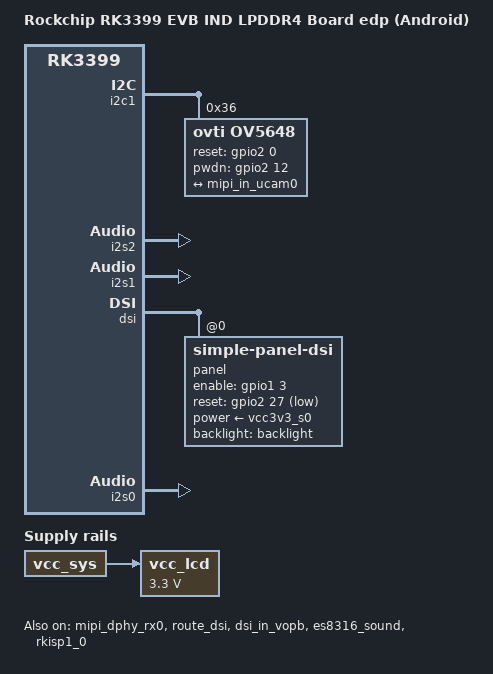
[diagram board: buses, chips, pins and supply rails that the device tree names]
// SPDX-License-Identifier: (GPL-2.0+ OR MIT)
/*
 * Copyright (c) 2019 Fuzhou Rockchip Electronics Co., Ltd
 */

/dts-v1/;

#include "rk3399-evb-ind-r70.dtsi"
#include "rk3399-android.dtsi"

/ {
	model = "Rockchip RK3399 EVB IND LPDDR4 Board edp (Android)";
	compatible = "rockchip,android", "rockchip,rk3399-evb-ind-lpddr4-android-r70", "rockchip,rk3399";
	chosen: chosen {
		bootargs = "earlycon=uart8250,mmio32,0xff1a0000 console=ttyFIQ0 androidboot.baseband=N/A androidboot.veritymode=enforcing androidboot.hardware=rk30board androidboot.console=ttyFIQ0 init=/init initrd=0x62000001,0x00800000 coherent_pool=1m";
	};

	iram: sram@ff8d0000 {
		compatible = "mmio-sram";
		reg = <0x0 0xff8d0000 0x0 0x20000>;
	};

	vcc_lcd: vcc-lcd {
		compatible = "regulator-fixed";
		regulator-name = "vcc_lcd";
		startup-delay-us = <20000>;
		enable-active-high;
		regulator-min-microvolt = <3300000>;
		regulator-max-microvolt = <3300000>;
		regulator-boot-on;
		vin-supply = <&vcc_sys>;
	};


	test-power {
		status = "okay";
	};
};

&backlight {
	enable-gpios = <&gpio1 2 GPIO_ACTIVE_HIGH>;
};

&dmac_bus {
	iram = <&iram>;
	rockchip,force-iram;
};

&dp_sound {
	status = "disabled";
};
/*
&edp {
	status = "disabled";
	force-hpd;

	ports {
		port@1 {
			reg = <1>;

			edp_out: endpoint {
				remote-endpoint = <&panel_in>;
			};
		};
	};
};

&edp_in_vopl {
	status = "disabled";
};
*/
&i2c1 {
	status = "okay";
	ov5648: ov5648@36 {
		compatible = "ovti,ov5648";
		status = "okay";
		reg = <0x36>;
		clocks = <&cru SCLK_CIF_OUT>;
		clock-names = "xvclk";
		/* avdd-supply = <>; */
		/* dvdd-supply = <>; */
		/* dovdd-supply = <>; */
		/* reset-gpios = <>; */
		//dovdd-supply = <&vcc1v8_dvp>;          
		reset-gpios = <&gpio2 0 GPIO_ACTIVE_HIGH>; 
		pwdn-gpios = <&gpio2 12 GPIO_ACTIVE_HIGH>;
		pinctrl-names = "rockchip,camera_default";
		pinctrl-0 = <&cif_clkout>;
		rockchip,camera-module-index = <0>;
		rockchip,camera-module-facing = "front";
		rockchip,camera-module-name = "default";
		rockchip,camera-module-lens-name = "default";                

		port {
			ucam_out0: endpoint {
				remote-endpoint = <&mipi_in_ucam0>;
				//remote-endpoint = <&mipi_in_ucam1>;
				data-lanes = <1 2>;
			};
		};
	};

};

&i2s2 {
	#sound-dai-cells = <0>;
	status = "okay";
};

&isp0_mmu {
	status = "okay";
};

&isp1_mmu {
	status = "okay";
};

&mipi_dphy_rx0 {
	status = "okay";

	ports {
		#address-cells = <1>;
		#size-cells = <0>;

		port@0 {
			reg = <0>;
			#address-cells = <1>;
			#size-cells = <0>;

			mipi_in_ucam0: endpoint@1 {
				reg = <1>;
				remote-endpoint = <&ucam_out0>;
				data-lanes = <1 2>;
			};
		};

		port@1 {
			reg = <1>;
			#address-cells = <1>;
			#size-cells = <0>;

			dphy_rx0_out: endpoint@0 {
				reg = <0>;
				remote-endpoint = <&isp0_mipi_in>;
			};
		};
	};
};
/*
&mipi_dphy_tx1rx1 {
	status = "okay";

	ports {
		#address-cells = <1>;
		#size-cells = <0>;

		port@0 {
			reg = <0>;
			#address-cells = <1>;
			#size-cells = <0>;

			mipi_in_ucam1: endpoint@1 {
				reg = <1>;
				remote-endpoint = <&ucam_out1>;
				data-lanes = <1 2>;
			};
		};

		port@1 {
			reg = <1>;
			#address-cells = <1>;
			#size-cells = <0>;

			dphy_tx1rx1_out: endpoint@0 {
				reg = <0>;
				remote-endpoint = <&isp1_mipi_in>;
			};
		};
	};
};
*/
&hdmi_sound {
	status = "disabled";
};

&route_dsi {
	status = "okay";
};

&dsi_in_vopl {
	status = "disabled";
};

&dsi_in_vopb {
	status = "okay";
};

&route_hdmi {
	status = "disabled";
	connect = <&vopl_out_hdmi>;
};

&i2s1 {
	#sound-dai-cells = <0>;
	status = "okay";
};

&es8316_sound {
	status = "okay";
};

&hdmi_in_vopb {
	status = "disabled";
};

&rkisp1_0 {
	status = "okay";

	port {
		#address-cells = <1>;
		#size-cells = <0>;

		isp0_mipi_in: endpoint@0 {
			reg = <0>;
			remote-endpoint = <&dphy_rx0_out>;
		};
	};
};

//JL101-CC1001-27F
&dsi {
	status = "okay";
	rockchip,lane-rate = <480>;
	panel@0 {
		compatible ="simple-panel-dsi";
		reg = <0>;
		backlight = <&backlight>;
		power-supply = <&vcc3v3_s0>;
		enable-gpios = <&gpio1 3 GPIO_ACTIVE_HIGH>;
		reset-gpios = <&gpio2 27 GPIO_ACTIVE_LOW>;
		
		dsi,flags = <(MIPI_DSI_MODE_VIDEO | MIPI_DSI_MODE_VIDEO_BURST)>;
		dsi,format = <MIPI_DSI_FMT_RGB888>;
		dsi,lanes = <4>;
		reset-delay-ms = <20>;
		init-delay-ms = <20>;
		enable-delay-ms = <120>;
		prepare-delay-ms = <120>;

		panel-init-sequence = [
        15 00 02 E0 00
		15 00 02 E1 93
		15 00 02 E2 65
		15 00 02 E3 F8
		15 00 02 80 03
		15 00 02 E0 01
		15 00 02 00 00
		15 00 02 01 5C
		15 00 02 17 00
		15 00 02 18 D7
		15 00 02 19 01
		15 00 02 1A 00
		15 00 02 1B D7		
		15 00 02 1C 01
		15 00 02 1F 70
		15 00 02 20 2D
		15 00 02 21 2D
		15 00 02 22 7E		
		15 00 02 24 FD
		15 00 02 37 19
		15 00 02 35 28
		15 00 02 38 05
		15 00 02 39 08
		15 00 02 3A 12
		15 00 02 3C 7E
		15 00 02 3D FF
		15 00 02 3E FF
		15 00 02 3F 7F
		15 00 02 0C 74
		15 00 02 40 06
		15 00 02 41 A0
		15 00 02 43 1E
		15 00 02 44 0B	
		15 00 02 55 01
		15 00 02 56 01
		15 00 02 57 6A
		15 00 02 58 09
		15 00 02 59 0A
		15 00 02 5A 2E
		15 00 02 5B 1A
		15 00 02 5C 15
		15 00 02 5D 7F		
		15 00 02 5E 5D
		15 00 02 5F 4B
		15 00 02 60 3E
		15 00 02 61 3A
		15 00 02 62 2B
		15 00 02 63 2F		
		15 00 02 64 19
		15 00 02 65 32
		15 00 02 66 31
		15 00 02 67 31
		15 00 02 68 4F
		15 00 02 69 3E
		15 00 02 6A 47
		15 00 02 6B 36
		15 00 02 6C 31
		15 00 02 6D 24
		15 00 02 6E 12
		15 00 02 6F 02
		15 00 02 70 7F		
		15 00 02 71 5D
		15 00 02 72 4B
		15 00 02 73 3E
		15 00 02 74 3A		
		15 00 02 75 2B
		15 00 02 76 2F
		15 00 02 77 19
		15 00 02 78 32
		15 00 02 79 31		
		15 00 02 7A 31
		15 00 02 7B 4F
		15 00 02 7C 3E
		15 00 02 7D 47
		15 00 02 7E 36		
		15 00 02 7F 31
		15 00 02 80 24
		15 00 02 81 12
		15 00 02 82 02
		15 00 02 E0 02
		15 00 02 00 52
		15 00 02 01 55
		15 00 02 02 55		
		15 00 02 03 50
		15 00 02 04 77
		15 00 02 05 57
		15 00 02 06 55
		15 00 02 07 4E
		15 00 02 08 4C
		15 00 02 09 5F		
		15 00 02 0A 4A
		15 00 02 0B 48
		15 00 02 0C 55
		15 00 02 0D 46
		15 00 02 0E 44
		15 00 02 0F 40		
		15 00 02 10 55
		15 00 02 11 55
		15 00 02 12 55
		15 00 02 13 55
		15 00 02 14 55
		15 00 02 15 55
		15 00 02 16 53		
		15 00 02 17 55
		15 00 02 18 55
		15 00 02 19 51
		15 00 02 1A 77
		15 00 02 1B 57
		15 00 02 1C 55
		15 00 02 1D 4F		
		15 00 02 1E 4D
		15 00 02 1F 5F
		15 00 02 20 4B
		15 00 02 21 49
		15 00 02 22 55
		15 00 02 23 47		
		15 00 02 24 45
		15 00 02 25 41
		15 00 02 26 55
		15 00 02 27 55		
		15 00 02 28 55
		15 00 02 29 55
		15 00 02 2A 55
		15 00 02 2B 55
		15 00 02 2C 13
		15 00 02 2D 15				
		15 00 02 2E 15
		15 00 02 2F 01
		15 00 02 30 37
		15 00 02 31 17
		15 00 02 32 15
		15 00 02 33 0D
		15 00 02 34 0F		
		15 00 02 35 15
		15 00 02 36 05
		15 00 02 37 07
		15 00 02 38 15
		15 00 02 39 09
		15 00 02 3A 0B
		15 00 02 3B 11
		15 00 02 3C 15
		15 00 02 3D 15
		15 00 02 3E 15
		15 00 02 3F 15
		15 00 02 40 15
		15 00 02 41 15
		15 00 02 42 12
		15 00 02 43 15
		15 00 02 44 15
		15 00 02 45 00
		15 00 02 46 37
		15 00 02 47 17
		15 00 02 48 15
		15 00 02 49 0C
		15 00 02 4A 0E
		15 00 02 4B 15
		15 00 02 4C 04
		15 00 02 4D 06
		15 00 02 4E 15
		15 00 02 4F 08
		15 00 02 50 0A
		15 00 02 51 10
		15 00 02 52 15
		15 00 02 53 15
		15 00 02 54 15
		15 00 02 55 15
		15 00 02 56 15
		15 00 02 57 15
		15 00 02 58 40
		15 00 02 5B 10
		15 00 02 5C 06		
		15 00 02 5D 40
		15 00 02 5E 00
		15 00 02 5F 00
		15 00 02 60 40
		15 00 02 61 03
		15 00 02 62 04
		15 00 02 63 6C
		15 00 02 64 6C
		15 00 02 65 75
		15 00 02 66 08
		15 00 02 67 B4
		15 00 02 68 08
		15 00 02 69 6C
		15 00 02 6A 6C
		15 00 02 6B 0C
		15 00 02 6D 00
		15 00 02 6E 00
		15 00 02 6F 88
		15 00 02 75 BB		
		15 00 02 76 00
		15 00 02 77 05
		15 00 02 78 2A
		15 00 02 E0 04
		15 00 02 36 49
		15 00 02 09 11
		15 00 02 0E 48
		15 00 02 E0 00
		05 78 01 11
		05 05 01 29
		15 00 02 35 00
		15 00 02 E0 00	
		    ]; 
						
		display-timings {
			native-mode = <&timing1>;
			timing1: timing1 {
				clock-frequency = <58000000>;
				hactive = <800>;
				vactive = <1280>;
				hback-porch = <20>;
				hfront-porch = <20>;
				vback-porch = <8>;
				vfront-porch = <30>;
				hsync-len = <20>;
				vsync-len = <4>;
				hsync-active = <0>;
				vsync-active = <0>;
				de-active = <0>;
				pixelclk-active = <0>;
			};
			timing2: timing2 {
				clock-frequency = <68000000>;
				hactive = <800>;
				vactive = <1280>;
				hback-porch = <20>;
				hfront-porch = <20>;
				vback-porch = <8>;
				vfront-porch = <30>;
				hsync-len = <20>;
				vsync-len = <4>;
				hsync-active = <0>;
				vsync-active = <0>;
				de-active = <0>;
				pixelclk-active = <0>;
			};
		};
	};
};

/*
 * if enable dp_sound, should disable spdif_sound and spdif_out
 */
&spdif_out {
	status = "disabled";
};

&spdif_sound {
	status = "disabled";
};

&i2s0 {
	#sound-dai-cells = <0>;
	status = "okay";
};
/*
&tc358749x_sound {
	status = "disabled";
};
*/
&pinctrl {
	lcd-panel {
		lcd_panel_reset: lcd-panel-reset {
			rockchip,pins = <1 23 RK_FUNC_GPIO &pcfg_pull_up>;
		};
	};
};

